# netx90_app register map
File version: 1.0
CPU: CM4 r0p1, little endian, MPU, FPU, 4 interrupt priority bits, 78 interrupts
Registers are 32-bit, read-write, reset 0x0 unless marked. A register's access mark holds for its fields unless they carry their own. Offsets are from the block's base; [hi:lo] are bit positions; {n}, {i} and the like mark numbered series.

## spi0_app
Base 0xFF8010C0
Same registers: spi1_app 0xFF801100, spi2_app 0xFF801140, spi_xpic_app 0xFF900380
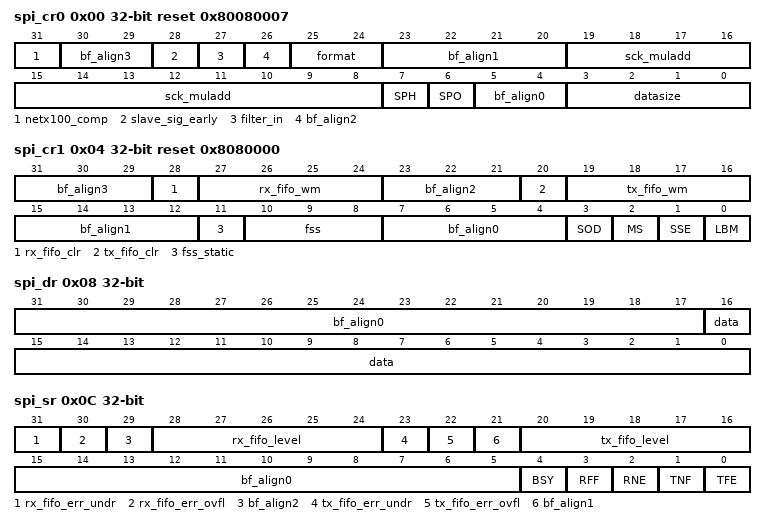
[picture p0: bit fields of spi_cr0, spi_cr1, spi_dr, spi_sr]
0x00 spi_cr0 reset 0x80080007 (reset mask 0x9B0FFFCF) — SPI control register 0 Registers 0x30..0x3C can be used instead of registers 0x00...0x24 to keep netx50 software compliant to netx100/500.
  [31] netx100_comp — Use netx100/500-compatible SPI mode: 0: start transfer after writing data 1: start transfer after setting CR_write or CR_read
  [30:29] bf_align3 — bitField alignment value for aeabi compatibility
  [28] slave_sig_early — Generate MISO in slave mode 1 SCK clock edge earlier than defined in the SPI specification. This is to compensate pad or sampling delays on fast data rates. However, hold timing problems could come up as MISO is generated very fast after the sampling SPI clock edge. If filter_in is enabled, it takes at least 3 system clocks to generate MISO after SCK. If filter_in is disabled, it takes at least 2 system clocks to generate MISO after SCK.
  [27] filter_in — Receive data is sampled every 10ns (100MHz system clock). If this bit is set, the stored receive value will be the result of a majority decision of the three sampling points around a SPI-clock edge (if two or more '1s! were sampled a '1' will be stored, else a '0' will be stored. In slave mode chip-select and SCK edges will also be detected by oversampling if this bit is set: An edge will be detected if the majority-result of 3 subsequent sampled values toggles. Input filtering should be used for sck_muladd<=0x200 (i.e. below 12.5MHz). Stable signal phases are too short with higher frequencies and input filtering cannot be used.
  [26] bf_align2 — bitField alignment value for aeabi compatibility
  [25:24] format — Frame format: 00: Motorola SPI frame format 01..11: reserved
  [23:20] bf_align1 — bitField alignment value for aeabi compatibility
  [19:8] sck_muladd — Serial clock rate multiply add value for master SCK generation. The SPI clock frequency is: f_spi_sck = (sck_muladd * 100)/4096 [MHz]. Default value 0x800 equals 50MHz SPI clock rate. All serial clock rates are derived from 100MHz netX system clock. Hence, all serial clock phases are multiples of 10ns. This leads to non-constant serial clock phases when a clock rate is programmed which cannot be generated by 100MHz/(2*n) without remainder. E.g. programming 0x4CC here will lead to a mean clock-rate of 30MHz. However, single clock high and low phases of 10ns and clock periods of 30ns will occur. This must be considered for serial device selection. E.g. using a 30MHz device which requires 33ns minimum clock period and a duty cycle of 50% will fail. Note: If sck_muladd is set to zero, SPI transfer will freeze. The SPI clock must not exceed (system frequency/4) in slave mode, if correct data sampling should always be guaranteed. Note: The value programmed here has no impact in slave mode.
  [7] SPH — Serial clock phase (netx500: CR_ncpha): 1: sample data at second clock edge, data is generated half a clock phase before sampling 0: sample data at first clock edge, data is generated half a clock phase before sampling
  [6] SPO — Serial clock polarity (netx500: CR_cpol): 0: idle: clock is low, first edge is rising 1: idle: clock is high, first edge is falling
  [5:4] bf_align0 — bitField alignment value for aeabi compatibility
  [3:0] datasize — DSS: data size select (transfer size = datasize + 1 bits): { | 0000...0010: reserved 0011: 4 bit 0100: 5 bit ... 0111: 8 bit ... 1111: 16 bit } Note: 16 bit TX-data-loss bug of netX50/netX5 is fixed since netX10.
0x04 spi_cr1 reset 0x8080000 (reset mask 0x1F1F0F0F) — SPI control register 1 Registers 0x30..0x3C can be used instead of registers 0x00...0x24 to keep netx50 software compliant to netx100/500.
  [31:29] bf_align3 — bitField alignment value for aeabi compatibility
  [28] rx_fifo_clr — Writing '1' to this bit will clear the receive FIFOs.
  [27:24] rx_fifo_wm — Receive FIFO watermark for IRQ generation
  [23:21] bf_align2 — bitField alignment value for aeabi compatibility
  [20] tx_fifo_clr — Writing '1' to this bit will clear the transmit FIFOs. Note: There must be at least 1 system clock idle after clear before writing new data to the FIFO. This is guaranteed by the netX internal bus structure and needs not being considered by software.
  [19:16] tx_fifo_wm — Transmit FIFO watermark for IRQ generation
  [15:12] bf_align1 — bitField alignment value for aeabi compatibility
  [11] fss_static — SPI static chip-select: { | 0: SPI chip-select will be toggled automatically before and after each transferred word according to fss and datasize. 1: SPI chip-select will be set statically according to the fss bits. }
  [10:8] fss — Frame or slave select. There are up to 3 external SPI chip-select signals. In master mode, the fss bits define the states of the chip-select signals. The inversion for low-active chip-selects (e.g. for Motorola SPI frame format) is done automatically depending on the value programmed to the 'format' bits. Example: To use the netX IO CS1 as chip-select, program '010' here, regardless whether the external chip-select is low or high active. In slave mode, the fss bits are a mask to select which netX input should be used as chip-select. Example: To use the netX IO CS0 as chip-select, program '001' here.
  [7:4] bf_align0 — bitField alignment value for aeabi compatibility
  [3] SOD — Slave mode output disable (to connect multiple slaves to one master): 0: MISO can be driven in slave mode 1: MISO is not driven in slave mode
  [2] MS — Mode select: 0: Module is configured as master 1: Module is configured as slave
  [1] SSE — SPI enable: 0: Module disabled 1: Module enabled
  [0] LBM — Loop back mode: 0: Internal loop back disabled 1: Internal loop back enabled, spi_cr0.filter_in must be set for loopback function
0x08 spi_dr (reset mask 0x1FFFF) — SPI data register Registers 0x30..0x3C can be used instead of registers 0x00...0x24 to keep netx50 software compliant to netx100/500. The SPI module has 2 FIFOs: One for transmit data and one for receive data. Read access: Received data byte is delivered from receive FIFO. Write access: Transmit data byte is written to send FIFO. Both FIFOs (receive and transmit) have a depth of 16. SPI master mode: MISO input data will be stored in the receive FIFO; transmit FIFO generates MOSI output data. SPI slave mode: MOSI input data will be stored in the receive FIFO; transmit FIFO generates MISO output data.
  [31:17] bf_align0 — bitField alignment value for aeabi compatibility
  [16:0] data — Transmit data: Only lowest bits according to spi_cr0.datasize will be sent. Receive data will be delivered on the lowest bits, unused bits (above spi_cr0.datasize) will be '0'. In slave mode transmit data is requested from the FIFO when the last bit of the currently transferred word is set to the MISO signal. If no next transmit data can be read from the FIFO until the current word's last bit was transferred, a FIFO underrun will occur in case chip-select does not go inactive at the next detected SCK edge.
0x0C spi_sr ro (reset mask 0xDFDF001F) — SPI status register Registers 0x30..0x3C can be used instead of registers 0x00...0x24 to keep netx50 software compliant to netx100/500. Note: Both FIFOs (receive and transmit) have a depth of 16.
  [31] rx_fifo_err_undr — Receive FIFO underrun error occurred, data is lost
  [30] rx_fifo_err_ovfl — Receive FIFO overflow error occurred, data is lost
  [29] bf_align2 — bitField alignment value for aeabi compatibility
  [28:24] rx_fifo_level — Receive FIFO level (number of received words to read out are left in FIFO)
  [23] tx_fifo_err_undr — Transmit FIFO underrun error occurred, data is lost
  [22] tx_fifo_err_ovfl — Transmit FIFO overflow error occurred, data is lost
  [21] bf_align1 — bitField alignment value for aeabi compatibility
  [20:16] tx_fifo_level — Transmit FIFO level (number of words to transmit are left in FIFO)
  [15:5] bf_align0 — bitField alignment value for aeabi compatibility
  [4] BSY — Device busy (1 if data is currently transmitted/received or the transmit FIFO is not empty)
  [3] RFF — Receive FIFO is full (1 if full)
  [2] RNE — Receive FIFO is not empty (0 if empty)
  [1] TNF — Transmit FIFO is not full (0 if full)
  [0] TFE — Transmit FIFO is empty (1 if empty)
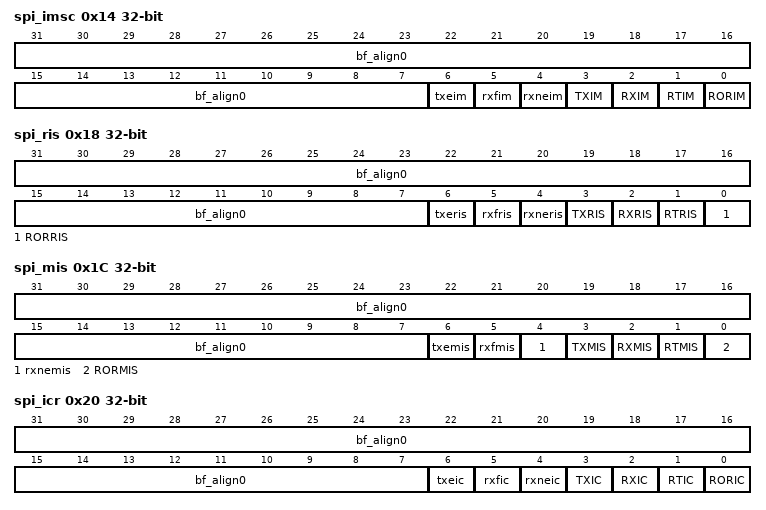
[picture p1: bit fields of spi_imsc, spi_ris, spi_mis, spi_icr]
0x14 spi_imsc (reset mask 0x7F) — SPI Interrupt Mask Set and Clear register: Registers 0x30..0x3C can be used instead of registers 0x00...0x24 to keep netx50 software compliant to netx100/500. IRQ mask is an AND-mask: only raw interrupts with mask bit set can generate a module IRQ. When writing this register, the corresponding interrupt is cleared similar to writing the register spi_icr. Note: The functionality of this register is similar to the corresponding SQI register sqi_irq_mask. However, in contrast to this register, setting bits in sqi_irq_mask does not clear the corresponding interrupts. Note: Both FIFOs (receive and transmit) have a depth of 16.
  [31:7] bf_align0 — bitField alignment value for aeabi compatibility
  [6] txeim — Transmit FIFO empty interrupt mask (for netx100/500 compliance)
  [5] rxfim — Receive FIFO full interrupt mask (for netx100/500 compliance)
  [4] rxneim — Receive FIFO not empty interrupt mask (for netx100/500 compliance)
  [3] TXIM — Transmit FIFO interrupt mask
  [2] RXIM — Receive FIFO interrupt mask
  [1] RTIM — Receive timeout interrupt mask
  [0] RORIM — Receive FIFO overrun interrupt mask
0x18 spi_ris ro (reset mask 0x7F) — SPI interrupt state before masking register (raw interrupt) Registers 0x30..0x3C can be used instead of registers 0x00...0x24 to keep netx50 software compliant to netx100/500. Note: Both FIFOs (receive and transmit) have a depth of 16.
  [31:7] bf_align0 — bitField alignment value for aeabi compatibility
  [6] txeris — Unmasked transmit FIFO empty interrupt state (for netx100/500 compliance) 1: transmit FIFO is empty 0: transmit FIFO is not empty
  [5] rxfris — Unmasked receive FIFO full interrupt state (for netx100/500 compliance) 1: receive FIFO is full 0: receive FIFO is not full
  [4] rxneris — Unmasked receive FIFO not empty interrupt state (for netx100/500 compliance) 1: receive FIFO is not empty 0: receive FIFO is empty
  [3] TXRIS — Unmasked transmit FIFO interrupt state 1: transmit FIFO level is below spi_cr1.tx_fifo_wm 0: transmit FIFO equals or is higher than spi_cr1.tx_fifo_wm
  [2] RXRIS — Unmasked receive FIFO interrupt state 1: receive FIFO is higher than spi_cr1.rx_fifo_wm 0: receive FIFO is equals or is below spi_cr1.rx_fifo_wm
  [1] RTRIS — Unmasked receive timeout interrupt state Timeout period are 32 SPI clock periods depending on adr_spi_cr0.sck_muladd 1: receive FIFO is not empty and not read out in the passed timeout period 0: receive FIFO is empty or read during the last timeout period
  [0] RORRIS — Unmasked receive FIFO overrun interrupt state 1: receive FIFO overrun error occurred 0: no receive FIFO overrun error occurred
0x1C spi_mis ro (reset mask 0x7F) — SPI interrupt status register Registers 0x30..0x3C can be used instead of registers 0x00...0x24 to keep netx50 software compliant to netx100/500. Note: Both FIFOs (receive and transmit) have a depth of 16.
  [31:7] bf_align0 — bitField alignment value for aeabi compatibility
  [6] txemis — Masked transmit FIFO empty interrupt state (for netx100/500 compliance)
  [5] rxfmis — Masked receive FIFO full interrupt state (for netx100/500 compliance)
  [4] rxnemis — Masked receive FIFO not empty interrupt state (for netx100/500 compliance)
  [3] TXMIS — Masked transmit FIFO interrupt state
  [2] RXMIS — Masked receive FIFO interrupt state
  [1] RTMIS — Masked receive timeout interrupt state
  [0] RORMIS — Masked receive FIFO overrun interrupt state
0x20 spi_icr (reset mask 0x7F) — SPI interrupt clear register Registers 0x30..0x3C can be used instead of registers 0x00...0x24 to keep netx50 software compliant to netx100/500. An interrupt is cleared by writing '1' to the according bit. Note: Both FIFOs (receive and transmit) have a depth of 16.
  [31:7] bf_align0 — bitField alignment value for aeabi compatibility
  [6] txeic — Clear transmit FIFO empty interrupt (for netx100/500 compliance)
  [5] rxfic — Clear receive FIFO full interrupt (for netx100/500 compliance)
  [4] rxneic — Clear receive FIFO not empty interrupt (for netx100/500 compliance)
  [3] TXIC — PL022 extension: clear transmit FIFO interrupt
  [2] RXIC — PL022 extension: clear receive FIFO interrupt
  [1] RTIC — Clear receive FIFO overrun interrupt
  [0] RORIC — Clear receive FIFO overrun interrupt Writing '1' here will clear the receive FIFO
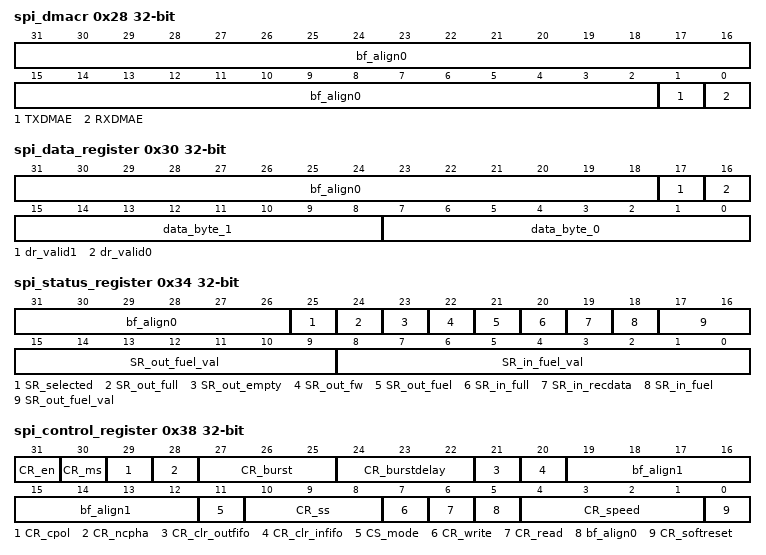
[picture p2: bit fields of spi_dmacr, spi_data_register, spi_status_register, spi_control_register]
0x28 spi_dmacr (reset mask 0x3) — SPI DMA control register
  [31:2] bf_align0 — bitField alignment value for aeabi compatibility
  [1] TXDMAE — Enable DMA for SPI transmit data. A single request will be generated if the transmit FIFO is not full and spi_cr1.SSE (module enable) is set. Burst requests to the DMA controller will be generated if at least 4 words are writable to the transmit FIFO (set DMA burst size to 4). If this bit is reset or the module is disabled, the DMA request signals will also be reset. Note: set dmac_chctrl.SBSize = 1 (i.e. burst size: 4) in the DMA controller.
  [0] RXDMAE — Enable DMA for SPI receive data. A single request will be generated if the receive FIFO is not empty and spi_cr1.SSE (module enable) is set. Burst request to the DMA controller will be generated if the receive FIFO contains at least 4 words (set DMA burst size to 4). If this bit is reset or the module is disabled, the DMA request signals will also be reset. Note: set dmac_chctrl.SBSize = 1 (i.e. burst size: 4) in the DMA controller.
0x30 spi_data_register (reset mask 0x3FFFF) — netx100/500 compliant SPI data register (DR) Registers 0x30..0x3C can be used instead of registers 0x00...0x24 to keep netx50 software compliant to netx100/500. 2 data bytes with valid bits. During a write access data_byte_1 and dr_valid1 must not be used. dr_valid0 must be set. In netx50 and later versions both FIFOs (receive and transmit) have a depth of 16, fill values are fixed to 4. To keep software compatible, not more than 8 bytes should be in netx100/500 FIFOs.
  [31:18] bf_align0 — bitField alignment value for aeabi compatibility
  [17] dr_valid1 — Obsolete, always 0
  [16] dr_valid0 — Valid bit for data_byte_0 This bit shows if data_byte_0 is valid and must be set during a FIFO write access.
  [15:8] data_byte_1 — Obsolete, don't use
  [7:0] data_byte_0
0x34 spi_status_register ro (reset mask 0x3FFFFFF) — netx100/500 compliant SPI status register (SR): Shows the actual status of the SPI interface. Bits 24..18 show occurred interrupts; writing ones into these bits clears the interrupts. Writing into other bits has no effect. In netx50 and later versions both FIFOs (receive and transmit) have a depth of 16, fill values are fixed to 4. To keep software compatible, not more than 8 bytes should be in netx100/500 FIFOs.
  [31:26] bf_align0 — bitField alignment value for aeabi compatibility
  [25] SR_selected — External master has access to SPI interface
  [24] SR_out_full — Output FIFO is full. This is only with netx100/500 an IRQ.
  [23] SR_out_empty — Output FIFO is empty in slave mode (equals spi_ris.txeris in netx50 and later versions)
  [22] SR_out_fw — netX is writing data too fast into output FIFO. Available as an IRQ only on netx100/500 (equals spi_sr.tx_fifo_err_ovfl in netx50 and later versions).
  [21] SR_out_fuel — Adjustable fill value of output FIFO reached (equals spi_ris.TXRIS in netx50 and later versions)
  [20] SR_in_full — Input FIFO is full (equals spi_ris.rxfris in netx50 and later versions)
  [19] SR_in_recdata — Valid data bytes in input FIFO (equals spi_ris.rxneris in netx50 and later versions)
  [18] SR_in_fuel — Adjustable fill value of input FIFO reached (equals spi_ris.RXRIS in netx50 and later versions)
  [17:9] SR_out_fuel_val — Output FIFO fill value (number of bytes)
  [8:0] SR_in_fuel_val — Input FIFO fill value (number of bytes)
0x38 spi_control_register (reset mask 0xFFF00FDF) — netx100/500 compliant SPI control register (CR)
  [31] CR_en — 1: enable 0: disable SPI interface
  [30] CR_ms — 1: master mode 0:slave mode
  [29] CR_cpol — 1: falling edge of SCK is primary 0: rising edge of SCK is primary
  [28] CR_ncpha — SPI clock phase mode (Note: meaning of this bit is inverted to functionality of bit spi_cr0.SPH): { | 0: change data on secondary SCK edge data is active on primary SCK edge 1: change data on primary SCK edge data is active on secondary SCK edge }
  [27:25] CR_burst — netx100/netx500 only, obsolete in later versions: burst length = 2^CR_burst
  [24:22] CR_burstdelay — netx100/netx500 only, obsolete in later versions: delay between transmission of 2 data bytes (0 to 7 SCK cycles)
  [21] CR_clr_outfifo — Clear output FIFO
  [20] CR_clr_infifo — Clear input FIFO
  [19:12] bf_align1 — bitField alignment value for aeabi compatibility
  [11] CS_mode — 1: chip select is generated automatically by the internal state machine 0: chip select is directly controlled by software (see bits CR_ss).
  [10:8] CR_ss — External slave select
  [7] CR_write — netx100/netx500 only, in later versions always '1': 1: enable SPI interface write data
  [6] CR_read — netx100/netx500 only, in later versions always '1': 1: enable SPI interface read data
  [5] bf_align0 — bitField alignment value for aeabi compatibility
  [4:1] CR_speed — Clock divider for SPI clock (2 - 2^16) If SPI clock rate is changed using spi_cr0.sck_muladd, this value will not be updated and may be incorrect There are 16 different SPI clocks frequencies to choose: 0000: 0.025 MHz (Note: Not compatible to netx100/500. '0000' freezes SCK in netx100/500.) 0001: 0.05 MHz 0010: 0.1 MHz 0011: 0.2 MHz 0100: 0.5 MHz 0101: 1 MHz 0110: 1.25 MHz 0111: 2 MHz 1000: 2.5 MHz 1001: 3.3333 MHz 1010: 5 MHz 1011: 10 MHz 1100: 12.5 MHz 1101: 16.6666 MHz 1110: 25 MHz 1111: 50 MHz
  [0] CR_softreset — write only: no function in netx100/netx500; later versions: clears IRQs and FIFOs
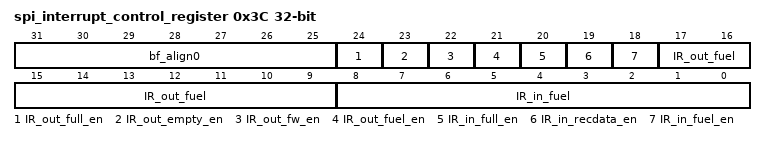
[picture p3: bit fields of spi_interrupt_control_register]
0x3C spi_interrupt_control_register (reset mask 0x1FFFFFF) — netx100/500 compliant SPI interrupt control register (IR) In netx50 and later versions both FIFOs (receive and transmit) have a depth of 16, fill values are fixed to 4. To keep software compatible, not more than 8 bytes should be in netx100/500 FIFOs.
  [31:25] bf_align0 — bitField alignment value for aeabi compatibility
  [24] IR_out_full_en — IRQ enable for irq_spi(6), netx100/netx500 only, always '0' in later versions
  [23] IR_out_empty_en — IRQ enable for irq_spi(5) (equals spi_imsc.rxeim in netx50 and later versions)
  [22] IR_out_fw_en — IRQ enable for irq_spi(4), netx100/netx500 only, always '0' in later versions
  [21] IR_out_fuel_en — IRQ enable for irq_spi(3) (equals spi_imsc.TXIM in netx50 and later versions)
  [20] IR_in_full_en — IRQ enable for irq_spi(2) (equals spi_imsc.txfim in netx50 and later versions)
  [19] IR_in_recdata_en — IRQ enable for irq_spi(1) (equals spi_imsc.txneim in netx50 and later versions)
  [18] IR_in_fuel_en — IRQ enable for irq_spi(0) (equals spi_imsc.RXIM in netx50 and later versions)
  [17:9] IR_out_fuel — Adjustable watermark level of output FIFO
  [8:0] IR_in_fuel — Adjustable watermark level of input FIFO
